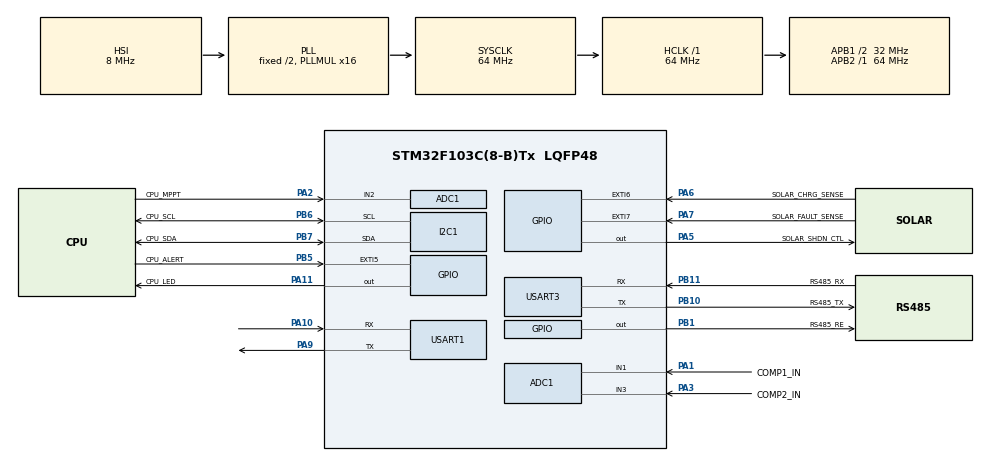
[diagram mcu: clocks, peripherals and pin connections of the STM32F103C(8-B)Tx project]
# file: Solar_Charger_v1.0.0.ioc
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ADC1.Channel-0\#ChannelRegularConversion=ADC_CHANNEL_1
ADC1.ContinuousConvMode=ENABLE
ADC1.NbrOfConversionFlag=1
ADC1.Rank-0\#ChannelRegularConversion=1
ADC1.SamplingTime-0\#ChannelRegularConversion=ADC_SAMPLETIME_1CYCLE_5
ADC1.master=1
I2C1.I2C_Mode=I2C_Fast
Mcu.Family=STM32F1
Mcu.Name=STM32F103C(8-B)Tx
Mcu.Package=LQFP48
NVIC.EXTI9_5_IRQn=true\:1\:0\:true\:false\:true\:true\:true
NVIC.PriorityGroup=NVIC_PRIORITYGROUP_2
NVIC.TIM1_UP_IRQn=true\:0\:0\:false\:false\:true\:true\:true
NVIC.TIM4_IRQn=true\:0\:0\:false\:false\:true\:true\:true
NVIC.USART1_IRQn=true\:0\:2\:false\:false\:true\:true\:true
NVIC.USART3_IRQn=true\:0\:2\:false\:false\:true\:true\:true
PA1.GPIO_Label=COMP1_IN
PA1.Signal=ADCx_IN1
PA10.Mode=Asynchronous
PA10.Signal=USART1_RX
PA11.GPIO_Label=CPU_LED
PA11.Signal=GPIO_Output
PA13.Mode=Serial_Wire
PA13.Signal=SYS_JTMS-SWDIO
PA14.Mode=Serial_Wire
PA14.Signal=SYS_JTCK-SWCLK
PA2.GPIO_Label=CPU_MPPT
PA2.Signal=ADCx_IN2
PA3.GPIO_Label=COMP2_IN
PA3.Signal=ADCx_IN3
PA5.GPIO_Label=SOLAR_SHDN_CTL
PA5.Signal=GPIO_Output
PA6.GPIO_Label=SOLAR_CHRG_SENSE
PA6.GPIO_PuPd=GPIO_PULLUP
PA6.Signal=GPXTI6
PA7.GPIO_Label=SOLAR_FAULT_SENSE
PA7.GPIO_PuPd=GPIO_PULLUP
PA7.Signal=GPXTI7
PA9.Mode=Asynchronous
PA9.Signal=USART1_TX
PB1.GPIO_Label=RS485_RE
PB1.Signal=GPIO_Output
PB10.GPIO_Label=RS485_TX
PB10.Mode=Asynchronous
PB10.Signal=USART3_TX
PB11.GPIO_Label=RS485_RX
PB11.Mode=Asynchronous
PB11.Signal=USART3_RX
PB5.GPIO_Label=CPU_ALERT
PB5.GPIO_PuPd=GPIO_PULLUP
PB5.Signal=GPXTI5
PB6.GPIO_Label=CPU_SCL
PB6.Mode=I2C
PB6.Signal=I2C1_SCL
PB7.GPIO_Label=CPU_SDA
PB7.Mode=I2C
PB7.Signal=I2C1_SDA
ProjectManager.HeapSize=0x400
ProjectManager.StackSize=0x800
ProjectManager.TargetToolchain=STM32CubeIDE
RCC.ADCPresc=RCC_ADCPCLK2_DIV8
RCC.AHBFreq_Value=64000000
RCC.APB1CLKDivider=RCC_HCLK_DIV2
RCC.APB1Freq_Value=32000000
RCC.APB1TimFreq_Value=64000000
RCC.APB2Freq_Value=64000000
RCC.APB2TimFreq_Value=64000000
RCC.HCLKFreq_Value=64000000
RCC.PLLMUL=RCC_PLL_MUL16
RCC.SYSCLKFreq_VALUE=64000000
RCC.SYSCLKSource=RCC_SYSCLKSOURCE_PLLCLK
RCC.USBFreq_Value=64000000
SH.ADCx_IN1.0=ADC1_IN1,IN1
SH.ADCx_IN2.0=ADC1_IN2,IN2
SH.ADCx_IN3.0=ADC1_IN3,IN3
TIM1.AutoReloadPreload=TIM_AUTORELOAD_PRELOAD_ENABLE
TIM1.Period=99
TIM1.Prescaler=6399
TIM4.AutoReloadPreload=TIM_AUTORELOAD_PRELOAD_ENABLE
TIM4.Period=999
TIM4.Prescaler=6399
USART1.VirtualMode=VM_ASYNC
USART3.VirtualMode=VM_ASYNC
VP_ADC1_Vref_Input.Mode=IN-Vrefint
VP_TIM1_VS_ClockSourceINT.Mode=Internal
VP_TIM4_VS_ClockSourceINT.Mode=Internal
board=custom

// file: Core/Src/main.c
/* USER CODE BEGIN Header */
/**
  ******************************************************************************
  * @file           : main.c
  * @brief          : Main program body
  ******************************************************************************
  * @attention
  *
  * <h2><center>&copy; Copyright (c) 2021 STMicroelectronics.
  * All rights reserved.</center></h2>
  *
  * This software component is licensed by ST under BSD 3-Clause license,
  * the "License"; You may not use this file except in compliance with the
  * License. You may obtain a copy of the License at:
  *                        opensource.org/licenses/BSD-3-Clause
  *
  ******************************************************************************
  */
/* USER CODE END Header */

#include "main.h"
#include "adc.h"
#include "i2c.h"
#include "tim.h"
#include "usart.h"
#include "gpio.h"

/* USER CODE BEGIN Includes */
#include "process_command.h"
#include "ina2xx.h"
#include "stdio.h"
/* USER CODE END Includes */

void SystemClock_Config(void);

int main(void)
{

  /* MCU Configuration--------------------------------------------------------*/

  /* Reset of all peripherals, Initializes the Flash interface and the Systick. */
  HAL_Init();

  /* Configure the system clock */
  SystemClock_Config();

  /* Initialize all configured peripherals */
  MX_GPIO_Init();
  MX_ADC1_Init();
  MX_I2C1_Init();
  MX_USART1_UART_Init();
  MX_USART3_UART_Init();
  MX_TIM1_Init();
  MX_TIM4_Init();
  /* USER CODE BEGIN 2 */
  HAL_GPIO_WritePin(CPU_LED_GPIO_Port, CPU_LED_Pin, RESET);
  if(ina2xx_Init(MON_IN_SLAVE, 0x5000, INA2xx_CONFIG_DEFAULT) == HAL_OK)
	  printf("MON_IN_SLAVE Init OK!\n");
  else
	  printf("MON_IN_SLAVE Init Error!\n");
  if(ina2xx_Init(MON_OUT_SLAVE, 0x5000, INA2xx_CONFIG_DEFAULT) == HAL_OK)
	  printf("MON_OUT_SLAVE Init OK!\n");
  else
	  printf("MON_OUT_SLAVE Init Error!\n");
  /* USER CODE END 2 */

  /* Infinite loop */
  /* USER CODE BEGIN WHILE */
  while (1)
  {
	  Process_Recieve_Command_1();
    /* USER CODE END WHILE */

  }
}

void SystemClock_Config(void)
{
  RCC_OscInitTypeDef RCC_OscInitStruct = {0};
  RCC_ClkInitTypeDef RCC_ClkInitStruct = {0};
  RCC_PeriphCLKInitTypeDef PeriphClkInit = {0};

  /** Initializes the CPU, AHB and APB busses clocks
  */
  RCC_OscInitStruct.OscillatorType = RCC_OSCILLATORTYPE_HSI;
  RCC_OscInitStruct.HSIState = RCC_HSI_ON;
  RCC_OscInitStruct.HSICalibrationValue = RCC_HSICALIBRATION_DEFAULT;
  RCC_OscInitStruct.PLL.PLLState = RCC_PLL_ON;
  RCC_OscInitStruct.PLL.PLLSource = RCC_PLLSOURCE_HSI_DIV2;
  RCC_OscInitStruct.PLL.PLLMUL = RCC_PLL_MUL16;
  if (HAL_RCC_OscConfig(&RCC_OscInitStruct) != HAL_OK)
  {
    Error_Handler();
  }
  /** Initializes the CPU, AHB and APB busses clocks
  */
  RCC_ClkInitStruct.ClockType = RCC_CLOCKTYPE_HCLK|RCC_CLOCKTYPE_SYSCLK
                              |RCC_CLOCKTYPE_PCLK1|RCC_CLOCKTYPE_PCLK2;
  RCC_ClkInitStruct.SYSCLKSource = RCC_SYSCLKSOURCE_PLLCLK;
  RCC_ClkInitStruct.AHBCLKDivider = RCC_SYSCLK_DIV1;
  RCC_ClkInitStruct.APB1CLKDivider = RCC_HCLK_DIV2;
  RCC_ClkInitStruct.APB2CLKDivider = RCC_HCLK_DIV1;

  if (HAL_RCC_ClockConfig(&RCC_ClkInitStruct, FLASH_LATENCY_2) != HAL_OK)
  {
    Error_Handler();
  }
  PeriphClkInit.PeriphClockSelection = RCC_PERIPHCLK_ADC;
  PeriphClkInit.AdcClockSelection = RCC_ADCPCLK2_DIV8;
  if (HAL_RCCEx_PeriphCLKConfig(&PeriphClkInit) != HAL_OK)
  {
    Error_Handler();
  }
}

void Error_Handler(void)
{
}

/************************ (C) COPYRIGHT STMicroelectronics *****END OF FILE****/
